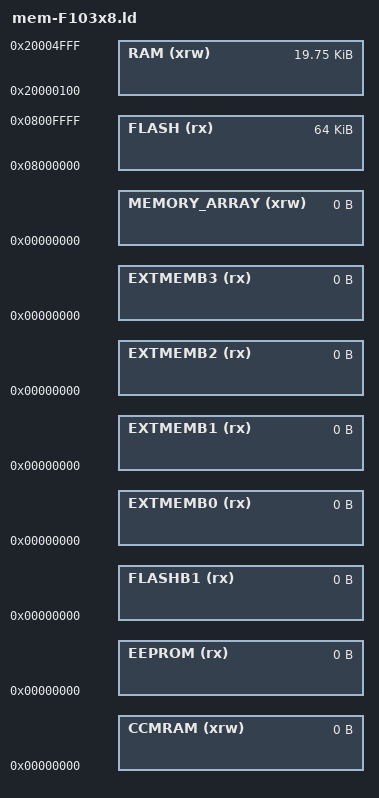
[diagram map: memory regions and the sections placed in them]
/*
 * Memory Spaces Definitions for STM32F103x8 (medium density).
 *
 * FLASH: 64K at 0x08000000. RAM: 20K at 0x20000000.
 *
 * The first 0x100 bytes of RAM are kept free for the copy of the vector
 * table that Interrupt::connectHandler() makes at SRAM_BASE. The table has
 * 59 entries (236 bytes). VTOR needs the table aligned to the next power of
 * two of its size, which is 256 bytes.
 *
 * The values below can be addressed in further linker scripts
 * using functions like 'ORIGIN(RAM)' or 'LENGTH(RAM)'.
 */

MEMORY
{
  RAM (xrw) : ORIGIN = 0x20000100, LENGTH = 20K-0x100
  CCMRAM (xrw) : ORIGIN = 0x00000000, LENGTH = 0
  FLASH (rx) : ORIGIN = 0x08000000, LENGTH = 64K
  EEPROM (rx) : ORIGIN = 0x00000000, LENGTH = 0
  FLASHB1 (rx) : ORIGIN = 0x00000000, LENGTH = 0
  EXTMEMB0 (rx) : ORIGIN = 0x00000000, LENGTH = 0
  EXTMEMB1 (rx) : ORIGIN = 0x00000000, LENGTH = 0
  EXTMEMB2 (rx) : ORIGIN = 0x00000000, LENGTH = 0
  EXTMEMB3 (rx) : ORIGIN = 0x00000000, LENGTH = 0
  MEMORY_ARRAY (xrw)  : ORIGIN = 0x00000000, LENGTH = 0
}
